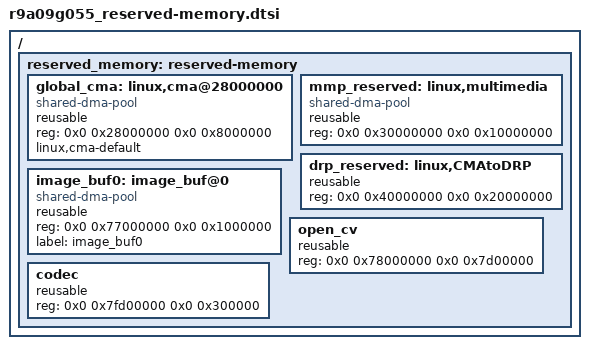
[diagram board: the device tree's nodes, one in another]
// SPDX-License-Identifier: GPL-2.0
/*
 * Device Tree Source for the RZ/V2MA reserved-memory part
 *
 * Copyright (C) 2023 Renesas Electronics Corp.
 */

/ {
    reserved_memory: reserved-memory {
        #address-cells = <2>;
        #size-cells = <2>;
        ranges;

        /* global autoconfigured region for contiguous allocations */
        global_cma: linux,cma@28000000 {
            compatible = "shared-dma-pool";
            reusable;
            reg = <0x0 0x28000000 0x0 0x8000000>;
            linux,cma-default;
        };

        /* device specific region for contiguous allocations */
        mmp_reserved: linux,multimedia {
            compatible = "shared-dma-pool";
            reusable;
            reg = <0x0 0x30000000 0x0 0x10000000>;
        };

        /* device specific region for contiguous allocations */
        drp_reserved: linux,CMAtoDRP {
            reusable;
            reg = <0x0 0x40000000 0x0 0x20000000>;
        };

        image_buf0: image_buf@0 {
            compatible = "shared-dma-pool";
            reusable;
            reg = <0x0 0x77000000 0x0 0x1000000>; //16MiB
            label = "image_buf0";
        };

        open_cv: open_cv {
            reusable;
            reg = <0x0 0x78000000 0x0 0x7d00000>; //125MiB
        };

        codec: codec {
            reusable;
            reg = <0x0 0x7fd00000 0x0 0x300000>; //3MiB
        };
    };
};
